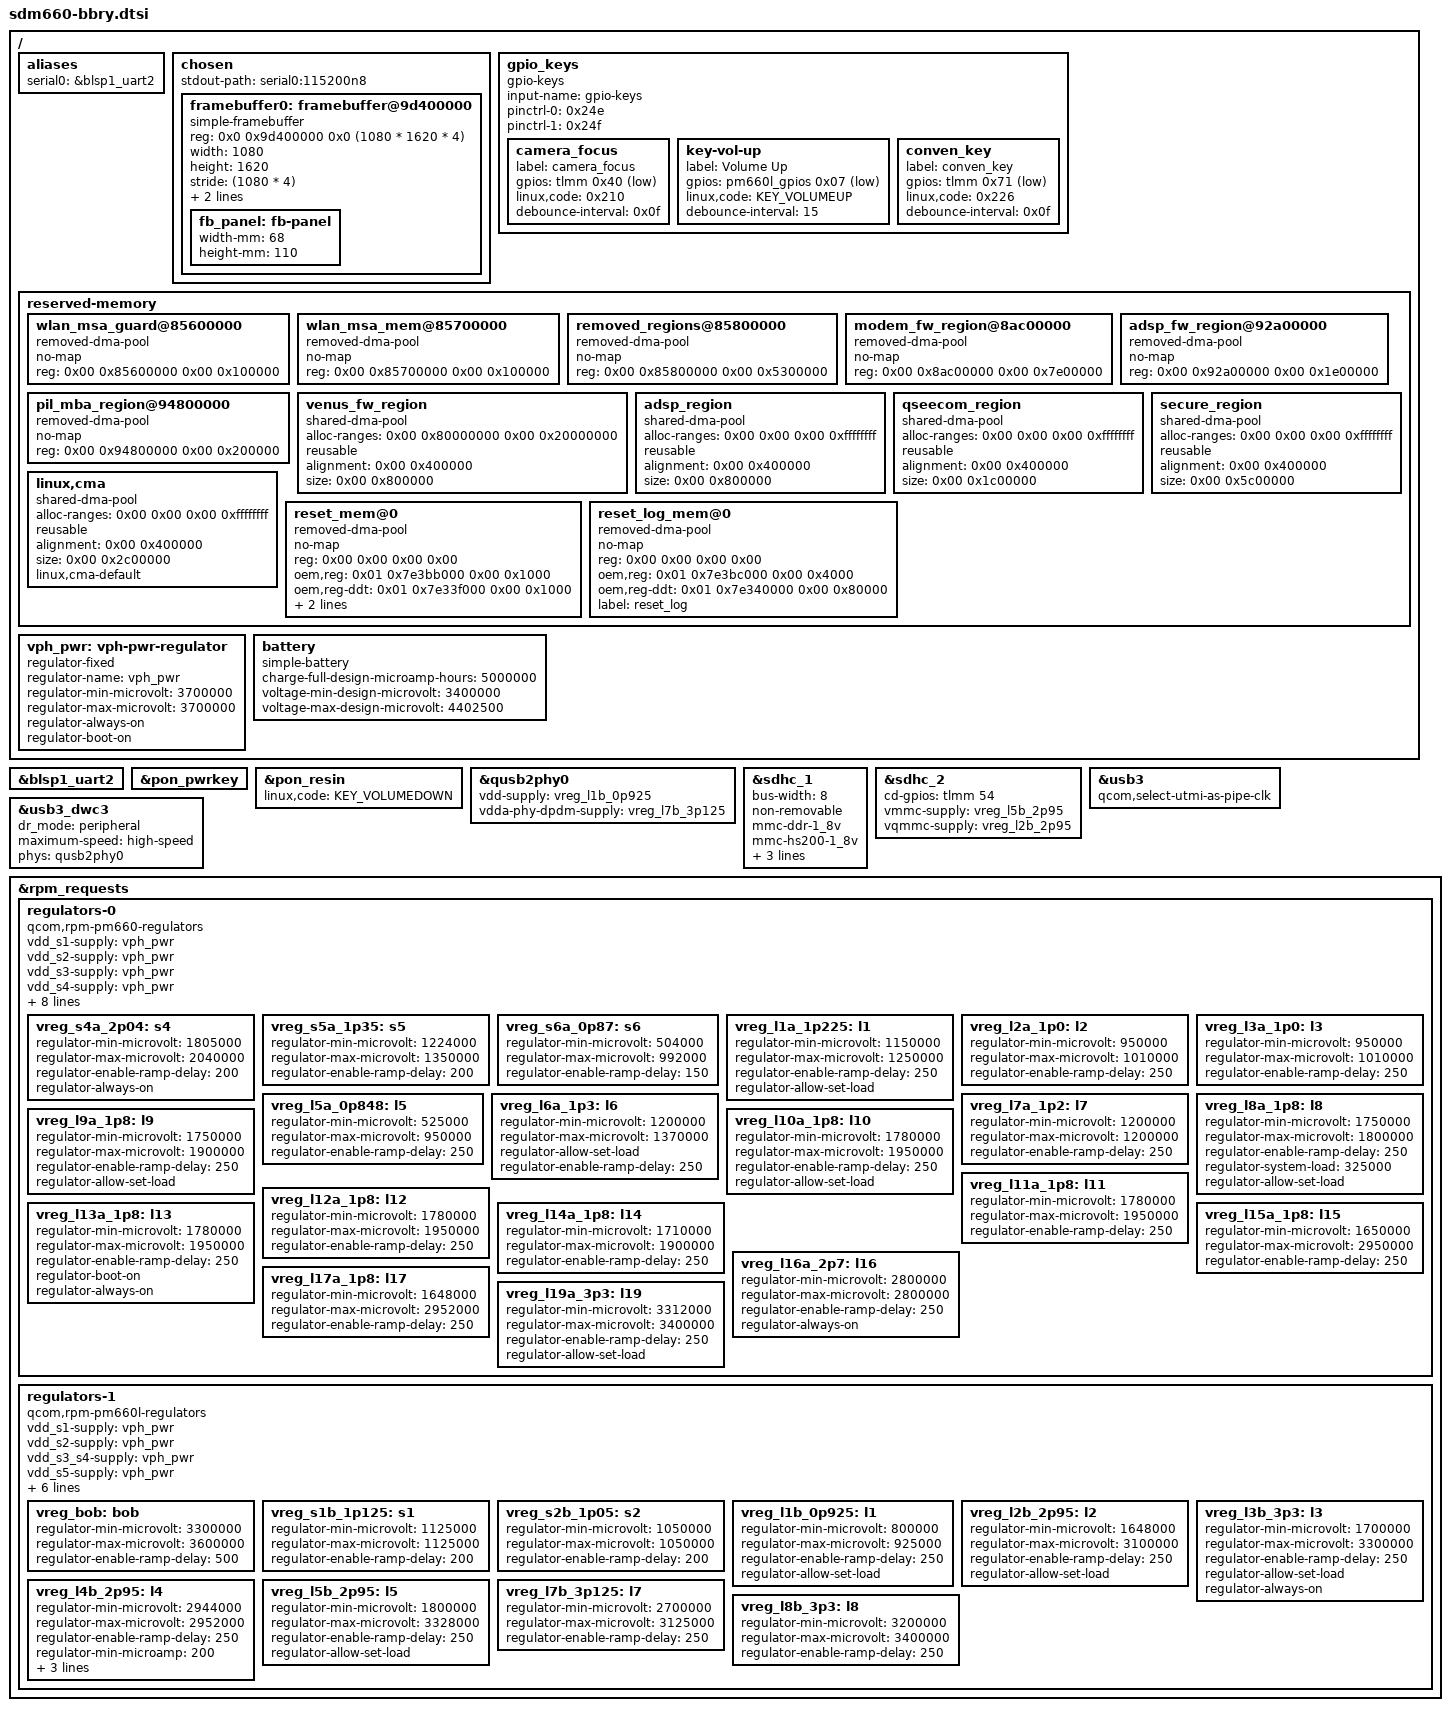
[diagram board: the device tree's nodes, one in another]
/dts-v1/;

#include "sdm636.dtsi"
#include "pm660.dtsi"
#include "pm660l.dtsi"
#include <dt-bindings/input/input.h>
#include <dt-bindings/input/gpio-keys.h>
#include <dt-bindings/pinctrl/qcom,pmic-gpio.h>

/delete-node/ &qhee_code;
/delete-node/ &tz_mem;

/ {

	aliases {
		serial0 = &blsp1_uart2;
	};

	chosen {
		#address-cells = <2>;
		#size-cells = <2>;
		ranges;

		stdout-path = "serial0:115200n8";

		framebuffer0: framebuffer@9d400000 {
			compatible = "simple-framebuffer";
			reg = <0x0 0x9d400000 0x0 (1080 * 1620 * 4)>;
			status = "okay";
			width = <1080>;
			height = <1620>;
			stride = <(1080 * 4)>;
			format = "a8r8g8b8";

			/* In order to allow simpledrm framebuffer to know
			 * physical dimensions */
			panel = <&fb_panel>;

			fb_panel: fb-panel {
				width-mm = <68>;
				height-mm = <110>;
			};
		};
	};

	gpio_keys {
		status = "okay";
		compatible = "gpio-keys";
		input-name = "gpio-keys";
		pinctrl-names = "tlmm_gpio_key_active", "tlmm_gpio_key_suspend";
		pinctrl-0 = <0x24e>;
		pinctrl-1 = <0x24f>;

		camera_focus {
				label = "camera_focus";
				gpios = <&tlmm 0x40 0x01>;
				linux,code = <0x210>;
				debounce-interval = <0x0f>;
		};

		key-vol-up {
				label = "Volume Up";
				gpios = <&pm660l_gpios 0x07 0x01>;
				linux,code = <KEY_VOLUMEUP>;
				debounce-interval = <15>;
		};

		conven_key {
				label = "conven_key";
				gpios = <&tlmm 0x71 0x01>;
				linux,code = <0x226>;
				debounce-interval = <0x0f>;
		};
	};

	reserved-memory {
		#address-cells = <0x02>;
		#size-cells = <0x02>;
		ranges;

		wlan_msa_guard@85600000 {
				compatible = "removed-dma-pool";
				no-map;
				reg = <0x00 0x85600000 0x00 0x100000>;
		};

		wlan_msa_mem@85700000 {
				compatible = "removed-dma-pool";
				no-map;
				reg = <0x00 0x85700000 0x00 0x100000>;
				linux,phandle = <0xfd>;
				phandle = <0xfd>;
		};

		removed_regions@85800000 {
				compatible = "removed-dma-pool";
				no-map;
				reg = <0x00 0x85800000 0x00 0x5300000>;
		};

		modem_fw_region@8ac00000 {
				compatible = "removed-dma-pool";
				no-map;
				reg = <0x00 0x8ac00000 0x00 0x7e00000>;
				linux,phandle = <0x102>;
				phandle = <0x102>;
		};

		adsp_fw_region@92a00000 {
				compatible = "removed-dma-pool";
				no-map;
				reg = <0x00 0x92a00000 0x00 0x1e00000>;
				linux,phandle = <0xff>;
				phandle = <0xff>;
		};

		pil_mba_region@94800000 {
				compatible = "removed-dma-pool";
				no-map;
				reg = <0x00 0x94800000 0x00 0x200000>;
				linux,phandle = <0x105>;
				phandle = <0x105>;
		};

		venus_fw_region {
				compatible = "shared-dma-pool";
				alloc-ranges = <0x00 0x80000000 0x00 0x20000000>;
				reusable;
				alignment = <0x00 0x400000>;
				size = <0x00 0x800000>;
				linux,phandle = <0xf8>;
				phandle = <0xf8>;
		};

		adsp_region {
			compatible = "shared-dma-pool";
			alloc-ranges = <0x00 0x00 0x00 0xffffffff>;
			reusable;
			alignment = <0x00 0x400000>;
			size = <0x00 0x800000>;
			linux,phandle = <0xee>;
			phandle = <0xee>;
		};

		qseecom_region {
				compatible = "shared-dma-pool";
				alloc-ranges = <0x00 0x00 0x00 0xffffffff>;
				reusable;
				alignment = <0x00 0x400000>;
				size = <0x00 0x1c00000>;
				linux,phandle = <0x10b>;
				phandle = <0x10b>;
		};

		secure_region {
				compatible = "shared-dma-pool";
				alloc-ranges = <0x00 0x00 0x00 0xffffffff>;
				reusable;
				alignment = <0x00 0x400000>;
				size = <0x00 0x5c00000>;
				linux,phandle = <0x10c>;
				phandle = <0x10c>;
		};

		linux,cma {
				compatible = "shared-dma-pool";
				alloc-ranges = <0x00 0x00 0x00 0xffffffff>;
				reusable;
				alignment = <0x00 0x400000>;
				size = <0x00 0x2c00000>;
				linux,cma-default;
		};

		reset_mem@0 {
				compatible = "removed-dma-pool";
				no-map;
				reg = <0x00 0x00 0x00 0x00>;
				oem,reg = <0x01 0x7e3bb000 0x00 0x1000>;
				oem,reg-ddt = <0x01 0x7e33f000 0x00 0x1000>;
				oem,writeable;
				label = "reset";
				linux,phandle = <0x283>;
				phandle = <0x283>;
		};

		reset_log_mem@0 {
				compatible = "removed-dma-pool";
				no-map;
				reg = <0x00 0x00 0x00 0x00>;
				oem,reg = <0x01 0x7e3bc000 0x00 0x4000>;
				oem,reg-ddt = <0x01 0x7e340000 0x00 0x80000>;
				label = "reset_log";
				linux,phandle = <0x284>;
				phandle = <0x284>;
		};
	};

    vph_pwr: vph-pwr-regulator {
		compatible = "regulator-fixed";
		regulator-name = "vph_pwr";
		regulator-min-microvolt = <3700000>;
		regulator-max-microvolt = <3700000>;
		regulator-always-on;
		regulator-boot-on;
	};

    battery: battery {
			compatible = "simple-battery";

			charge-full-design-microamp-hours = <5000000>;
			voltage-min-design-microvolt = <3400000>;
			voltage-max-design-microvolt = <4402500>;
	};
};

&blsp1_uart2 {
	status = "okay";
};

&pon_pwrkey {
	status = "okay";
};

&pon_resin {
	linux,code = <KEY_VOLUMEDOWN>;

	status = "okay";
};

&qusb2phy0 {
	vdd-supply = <&vreg_l1b_0p925>;
	vdda-phy-dpdm-supply = <&vreg_l7b_3p125>;

	status = "okay";
};


&sdhc_1 {
	bus-width = <8>;
	non-removable;
	mmc-ddr-1_8v;
	mmc-hs200-1_8v;
	mmc-hs400-1_8v;
	vmmc-supply = <&vreg_l4b_2p95>;
	vqmmc-supply = <&vreg_l8a_1p8>;

	status = "okay";
};

&sdhc_2 {
	cd-gpios = <&tlmm 54 GPIO_ACTIVE_HIGH>;

	vmmc-supply = <&vreg_l5b_2p95>;
	vqmmc-supply = <&vreg_l2b_2p95>;

	status = "okay";
};

&usb3 {
	qcom,select-utmi-as-pipe-clk;

	status = "okay";
};

&usb3_dwc3 {
	dr_mode = "peripheral";

	maximum-speed = "high-speed";
	phys = <&qusb2phy0>;
	phy-names = "usb2-phy";

	status = "okay";
};

&rpm_requests {
	regulators-0 {
		compatible = "qcom,rpm-pm660-regulators";

		vdd_s1-supply = <&vph_pwr>;
		vdd_s2-supply = <&vph_pwr>;
		vdd_s3-supply = <&vph_pwr>;
		vdd_s4-supply = <&vph_pwr>;
		vdd_s5-supply = <&vph_pwr>;
		vdd_s6-supply = <&vph_pwr>;

		vdd_l1_l6_l7-supply = <&vreg_s5a_1p35>;
		vdd_l2_l3-supply = <&vreg_s2b_1p05>;
		vdd_l5-supply = <&vreg_s2b_1p05>;
		vdd_l8_l9_l10_l11_l12_l13_l14-supply = <&vreg_s4a_2p04>;
		vdd_l15_l16_l17_l18_l19-supply = <&vreg_bob>;

		/*
		 * S1A (FTAPC0), S2A (FTAPC1), S3A (HFAPC1) are managed
		 * by the Core Power Reduction hardened (CPRh) and the
		 * Operating State Manager (OSM) HW automatically.
		 */

		vreg_s4a_2p04: s4 {
			regulator-min-microvolt = <1805000>;
			regulator-max-microvolt = <2040000>;
			regulator-enable-ramp-delay = <200>;
			regulator-always-on;
		};

		vreg_s5a_1p35: s5 {
			regulator-min-microvolt = <1224000>;
			regulator-max-microvolt = <1350000>;
			regulator-enable-ramp-delay = <200>;
		};

		vreg_s6a_0p87: s6 {
			regulator-min-microvolt = <504000>;
			regulator-max-microvolt = <992000>;
			regulator-enable-ramp-delay = <150>;
		};

		/* LDOs */
		vreg_l1a_1p225: l1 {
			regulator-min-microvolt = <1150000>;
			regulator-max-microvolt = <1250000>;
			regulator-enable-ramp-delay = <250>;
			regulator-allow-set-load;
		};

		vreg_l2a_1p0: l2 {
			regulator-min-microvolt = <950000>;
			regulator-max-microvolt = <1010000>;
			regulator-enable-ramp-delay = <250>;
		};

		vreg_l3a_1p0: l3 {
			regulator-min-microvolt = <950000>;
			regulator-max-microvolt = <1010000>;
			regulator-enable-ramp-delay = <250>;
		};

		vreg_l5a_0p848: l5 {
			regulator-min-microvolt = <525000>;
			regulator-max-microvolt = <950000>;
			regulator-enable-ramp-delay = <250>;
		};

		vreg_l6a_1p3: l6 {
			regulator-min-microvolt = <1200000>;
			regulator-max-microvolt = <1370000>;
			regulator-allow-set-load;
			regulator-enable-ramp-delay = <250>;
		};

		vreg_l7a_1p2: l7 {
			regulator-min-microvolt = <1200000>;
			regulator-max-microvolt = <1200000>;
			regulator-enable-ramp-delay = <250>;
		};

		vreg_l8a_1p8: l8 {
			regulator-min-microvolt = <1750000>;
			regulator-max-microvolt = <1800000>;
			regulator-enable-ramp-delay = <250>;
			regulator-system-load = <325000>;
			regulator-allow-set-load;
		};

		vreg_l9a_1p8: l9 {
			regulator-min-microvolt = <1750000>;
			regulator-max-microvolt = <1900000>;
			regulator-enable-ramp-delay = <250>;
			regulator-allow-set-load;
		};

		vreg_l10a_1p8: l10 {
			regulator-min-microvolt = <1780000>;
			regulator-max-microvolt = <1950000>;
			regulator-enable-ramp-delay = <250>;
			regulator-allow-set-load;
		};

		vreg_l11a_1p8: l11 {
			regulator-min-microvolt = <1780000>;
			regulator-max-microvolt = <1950000>;
			regulator-enable-ramp-delay = <250>;
		};

		vreg_l12a_1p8: l12 {
			regulator-min-microvolt = <1780000>;
			regulator-max-microvolt = <1950000>;
			regulator-enable-ramp-delay = <250>;
		};

		/* This gives power to the LPDDR4: never turn it off! */
		vreg_l13a_1p8: l13 {
			regulator-min-microvolt = <1780000>;
			regulator-max-microvolt = <1950000>;
			regulator-enable-ramp-delay = <250>;
			regulator-boot-on;
			regulator-always-on;
		};

		vreg_l14a_1p8: l14 {
			regulator-min-microvolt = <1710000>;
			regulator-max-microvolt = <1900000>;
			regulator-enable-ramp-delay = <250>;
		};

		vreg_l15a_1p8: l15 {
			regulator-min-microvolt = <1650000>;
			regulator-max-microvolt = <2950000>;
			regulator-enable-ramp-delay = <250>;
		};

		vreg_l16a_2p7: l16 {
			regulator-min-microvolt = <2800000>;
			regulator-max-microvolt = <2800000>;
			regulator-enable-ramp-delay = <250>;
			regulator-always-on;
		};

		vreg_l17a_1p8: l17 {
			regulator-min-microvolt = <1648000>;
			regulator-max-microvolt = <2952000>;
			regulator-enable-ramp-delay = <250>;
		};

		vreg_l19a_3p3: l19 {
			regulator-min-microvolt = <3312000>;
			regulator-max-microvolt = <3400000>;
			regulator-enable-ramp-delay = <250>;
			regulator-allow-set-load;
		};
	};

	regulators-1 {
		compatible = "qcom,rpm-pm660l-regulators";

		vdd_s1-supply = <&vph_pwr>;
		vdd_s2-supply = <&vph_pwr>;
		vdd_s3_s4-supply = <&vph_pwr>;
		vdd_s5-supply = <&vph_pwr>;
		vdd_s6-supply = <&vph_pwr>;

		vdd_l1_l9_l10-supply = <&vreg_s2b_1p05>;
		vdd_l2-supply = <&vreg_bob>;
		vdd_l3_l5_l7_l8-supply = <&vreg_bob>;
		vdd_l4_l6-supply = <&vreg_bob>;
		vdd_bob-supply = <&vph_pwr>;

		vreg_bob: bob {
			regulator-min-microvolt = <3300000>;
			regulator-max-microvolt = <3600000>;
			regulator-enable-ramp-delay = <500>;
		};

		vreg_s1b_1p125: s1 {
			regulator-min-microvolt = <1125000>;
			regulator-max-microvolt = <1125000>;
			regulator-enable-ramp-delay = <200>;
		};

		vreg_s2b_1p05: s2 {
			regulator-min-microvolt = <1050000>;
			regulator-max-microvolt = <1050000>;
			regulator-enable-ramp-delay = <200>;
		};

		/* LDOs */
		vreg_l1b_0p925: l1 {
			regulator-min-microvolt = <800000>;
			regulator-max-microvolt = <925000>;
			regulator-enable-ramp-delay = <250>;
			regulator-allow-set-load;
		};

		/* SDHCI 3.3V signal doesn't seem to be supported. */
		vreg_l2b_2p95: l2 {
			regulator-min-microvolt = <1648000>;
			regulator-max-microvolt = <3100000>;
			regulator-enable-ramp-delay = <250>;
			regulator-allow-set-load;
		};

		vreg_l3b_3p3: l3 {
			regulator-min-microvolt = <1700000>;
			regulator-max-microvolt = <3300000>;
			regulator-enable-ramp-delay = <250>;
			regulator-allow-set-load;
			regulator-always-on;
		};

		vreg_l4b_2p95: l4 {
			regulator-min-microvolt = <2944000>;
			regulator-max-microvolt = <2952000>;
			regulator-enable-ramp-delay = <250>;

			regulator-min-microamp = <200>;
			regulator-max-microamp = <600000>;
			regulator-system-load = <570000>;
			regulator-allow-set-load;
		};

		/*
		 * Downstream specifies a range of 1721-3600mV,
		 * but the only assigned consumers are SDHCI2 VMMC
		 * and Coresight QPDI that both request pinned 2.95V.
		 * Tighten the range to 1.8-3.328 (closest to 3.3) to
		 * make the mmc driver happy.
		 */
		vreg_l5b_2p95: l5 {
			regulator-min-microvolt = <1800000>;
			regulator-max-microvolt = <3328000>;
			regulator-enable-ramp-delay = <250>;
			regulator-allow-set-load;
		};

		vreg_l7b_3p125: l7 {
			regulator-min-microvolt = <2700000>;
			regulator-max-microvolt = <3125000>;
			regulator-enable-ramp-delay = <250>;
		};

		vreg_l8b_3p3: l8 {
			regulator-min-microvolt = <3200000>;
			regulator-max-microvolt = <3400000>;
			regulator-enable-ramp-delay = <250>;
		};
	};
};
